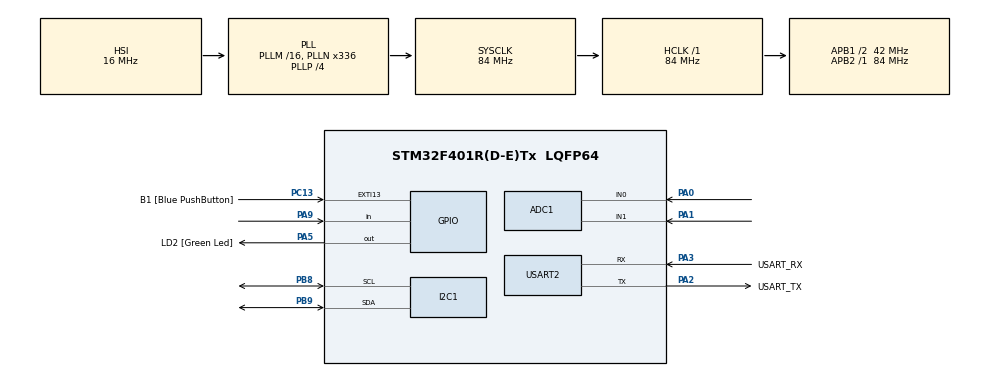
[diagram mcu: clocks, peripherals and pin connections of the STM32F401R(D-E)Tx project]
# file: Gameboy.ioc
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ADC1.Channel-0\#ChannelRegularConversion=ADC_CHANNEL_0
ADC1.Channel-1\#ChannelRegularConversion=ADC_CHANNEL_0
ADC1.ContinuousConvMode=ENABLE
ADC1.DMAContinuousRequests=ENABLE
ADC1.NbrOfConversion=2
ADC1.NbrOfConversionFlag=1
ADC1.Rank-0\#ChannelRegularConversion=1
ADC1.Rank-1\#ChannelRegularConversion=2
ADC1.SamplingTime-0\#ChannelRegularConversion=ADC_SAMPLETIME_480CYCLES
ADC1.SamplingTime-1\#ChannelRegularConversion=ADC_SAMPLETIME_480CYCLES
ADC1.master=1
Dma.ADC1.0.Direction=DMA_PERIPH_TO_MEMORY
Dma.ADC1.0.FIFOMode=DMA_FIFOMODE_DISABLE
Dma.ADC1.0.Instance=DMA2_Stream0
Dma.ADC1.0.MemDataAlignment=DMA_MDATAALIGN_HALFWORD
Dma.ADC1.0.MemInc=DMA_MINC_ENABLE
Dma.ADC1.0.Mode=DMA_CIRCULAR
Dma.ADC1.0.PeriphDataAlignment=DMA_PDATAALIGN_HALFWORD
Dma.ADC1.0.PeriphInc=DMA_PINC_DISABLE
Dma.ADC1.0.Priority=DMA_PRIORITY_LOW
Dma.Request0=ADC1
FREERTOS.Mutexes01=DataMutex,Dynamic,NULL,Available
FREERTOS.Tasks01=GameTask,24,512,StartGameTask,Default,NULL,Dynamic,NULL,NULL;InputTask,40,128,StartInputTask,Default,NULL,Dynamic,NULL,NULL
I2C1.I2C_Mode=I2C_Fast
Mcu.Family=STM32F4
Mcu.Name=STM32F401R(D-E)Tx
Mcu.Package=LQFP64
NVIC.ADC_IRQn=true\:5\:0\:false\:false\:true\:true\:true\:true\:true
NVIC.DMA2_Stream0_IRQn=true\:5\:0\:false\:false\:true\:true\:false\:true\:true
NVIC.PriorityGroup=NVIC_PRIORITYGROUP_4
PA0-WKUP.Signal=ADCx_IN0
PA1.Signal=ADCx_IN1
PA13.GPIO_Label=TMS
PA13.Mode=Trace_Asynchronous_SW
PA13.Signal=SYS_JTMS-SWDIO
PA14.GPIO_Label=TCK
PA14.Mode=Trace_Asynchronous_SW
PA14.Signal=SYS_JTCK-SWCLK
PA2.GPIO_Label=USART_TX
PA2.GPIO_Mode=GPIO_MODE_AF_PP
PA2.GPIO_PuPd=GPIO_NOPULL
PA2.GPIO_Speed=GPIO_SPEED_FREQ_LOW
PA2.Mode=Asynchronous
PA2.Signal=USART2_TX
PA3.GPIO_Label=USART_RX
PA3.GPIO_Mode=GPIO_MODE_AF_PP
PA3.GPIO_PuPd=GPIO_NOPULL
PA3.GPIO_Speed=GPIO_SPEED_FREQ_LOW
PA3.Mode=Asynchronous
PA3.Signal=USART2_RX
PA5.GPIO_Label=LD2 [Green Led]
PA5.GPIO_Mode=GPIO_MODE_OUTPUT_PP
PA5.GPIO_PuPd=GPIO_NOPULL
PA5.GPIO_Speed=GPIO_SPEED_FREQ_LOW
PA5.Signal=GPIO_Output
PA9.Signal=GPIO_Input
PB3.GPIO_Label=SWO
PB3.Mode=Trace_Asynchronous_SW
PB3.Signal=SYS_JTDO-SWO
PB8.Mode=I2C
PB8.Signal=I2C1_SCL
PB9.Mode=I2C
PB9.Signal=I2C1_SDA
PC13-ANTI_TAMP.GPIO_Label=B1 [Blue PushButton]
PC13-ANTI_TAMP.GPIO_ModeDefaultEXTI=GPIO_MODE_IT_FALLING
PC13-ANTI_TAMP.GPIO_PuPd=GPIO_NOPULL
PC13-ANTI_TAMP.Signal=GPXTI13
PC14-OSC32_IN.Mode=LSE-External-Oscillator
PC14-OSC32_IN.Signal=RCC_OSC32_IN
PC15-OSC32_OUT.Mode=LSE-External-Oscillator
PC15-OSC32_OUT.Signal=RCC_OSC32_OUT
PH0\ -\ OSC_IN.Mode=HSE-External-Clock-Source
PH0\ -\ OSC_IN.Signal=RCC_OSC_IN
PH1\ -\ OSC_OUT.Mode=HSE-External-Clock-Source
PH1\ -\ OSC_OUT.Signal=RCC_OSC_OUT
ProjectManager.HeapSize=0x200
ProjectManager.StackSize=0x400
ProjectManager.TargetToolchain=STM32CubeIDE
RCC.48MHZClocksFreq_Value=48000000
RCC.AHBFreq_Value=84000000
RCC.APB1CLKDivider=RCC_HCLK_DIV2
RCC.APB1Freq_Value=42000000
RCC.APB1TimFreq_Value=84000000
RCC.APB2Freq_Value=84000000
RCC.APB2TimFreq_Value=84000000
RCC.CortexFreq_Value=84000000
RCC.HCLKFreq_Value=84000000
RCC.HSE_VALUE=8000000
RCC.HSI_VALUE=16000000
RCC.PLLN=336
RCC.PLLP=RCC_PLLP_DIV4
RCC.PLLQ=7
RCC.SYSCLKFreq_VALUE=84000000
RCC.SYSCLKSource=RCC_SYSCLKSOURCE_PLLCLK
RCC.VCOOutputFreq_Value=336000000
SH.ADCx_IN0.0=ADC1_IN0,IN0
SH.ADCx_IN1.0=ADC1_IN1,IN1
USART2.VirtualMode=VM_ASYNC
VP_FREERTOS_VS_CMSIS_V2.Mode=CMSIS_V2
board=NUCLEO-F401RE

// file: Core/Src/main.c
/* USER CODE BEGIN Header */
/**
  ******************************************************************************
  * @file           : main.c
  * @brief          : Main program body
  ******************************************************************************
  */
/* USER CODE END Header */
#include "main.h"
#include "cmsis_os.h"
#include "adc.h"
#include "dma.h"
#include "i2c.h"
#include "usart.h"
#include "gpio.h"

/* USER CODE BEGIN Includes */
#include "ssd1306.h"
#include "ssd1306_fonts.h"
#include "joystick.h"

// Note: Ensure you have included SEGGER headers if you use them below
// #include "SEGGER_SYSVIEW.h"
#include "SEGGER_SYSVIEW.h"
/* USER CODE END Includes */

/* USER CODE BEGIN PV */
#define DWT_CTRL (*(volatile uint32_t*) 0xE0001000)

// The array that DMA will fill automatically.
// 'volatile' is critical so the compiler knows hardware changes it.
volatile uint16_t adcValues[2];
/* USER CODE END PV */

void SystemClock_Config(void);
void MX_FREERTOS_Init(void);

int main(void)
{

  /* MCU Configuration--------------------------------------------------------*/

  /* Reset of all peripherals, Initializes the Flash interface and the Systick. */
  HAL_Init();

  /* Configure the system clock */
  SystemClock_Config();

  /* Initialize all configured peripherals */
  MX_GPIO_Init();
  MX_DMA_Init();
  MX_USART2_UART_Init();
  MX_ADC1_Init();
  MX_I2C1_Init();

  /* USER CODE BEGIN 2 */
  ssd1306_Init();
  Joystick_Init();

// --- DMA START (Correct!) ---
  if (HAL_ADC_Start_DMA(&hadc1, (uint32_t*)adcValues, 2) != HAL_OK) {
	  Error_Handler();
  }

// --- SYSTEMVIEW SETUP ---

// 1. Enable Cycle Counter (Required for timestamps)
  DWT_CTRL |= (1<<0);

// 2. Setup Priority Grouping (Required by FreeRTOS)
  NVIC_SetPriorityGrouping(0);

// 3. Configure SystemView (Initialize buffers)
// --- FIX: Uncomment this ---
  SEGGER_SYSVIEW_Conf();

// 4. Start Recording
// --- FIX: Uncomment this ---
//  SEGGER_SYSVIEW_Start();

// Note: I commented out SEGGER_UART_init because usually SystemView uses RTT.
// If you are sure you are using UART mode, uncomment it.
  SEGGER_UART_init(500000);

  /* USER CODE END 2 */

  /* Init scheduler */
  osKernelInitialize();  /* Call init function for freertos objects (in cmsis_os2.c) */
  MX_FREERTOS_Init();

  /* Start scheduler */
  osKernelStart();

  /* We should never get here as control is now taken by the scheduler */

  /* Infinite loop */
  while (1)
  {

  }
}

void SystemClock_Config(void)
{
  RCC_OscInitTypeDef RCC_OscInitStruct = {0};
  RCC_ClkInitTypeDef RCC_ClkInitStruct = {0};

  /** Configure the main internal regulator output voltage
  */
  __HAL_RCC_PWR_CLK_ENABLE();
  __HAL_PWR_VOLTAGESCALING_CONFIG(PWR_REGULATOR_VOLTAGE_SCALE2);

  /** Initializes the RCC Oscillators according to the specified parameters
  * in the RCC_OscInitTypeDef structure.
  */
  RCC_OscInitStruct.OscillatorType = RCC_OSCILLATORTYPE_HSI;
  RCC_OscInitStruct.HSIState = RCC_HSI_ON;
  RCC_OscInitStruct.HSICalibrationValue = RCC_HSICALIBRATION_DEFAULT;
  RCC_OscInitStruct.PLL.PLLState = RCC_PLL_ON;
  RCC_OscInitStruct.PLL.PLLSource = RCC_PLLSOURCE_HSI;
  RCC_OscInitStruct.PLL.PLLM = 16;
  RCC_OscInitStruct.PLL.PLLN = 336;
  RCC_OscInitStruct.PLL.PLLP = RCC_PLLP_DIV4;
  RCC_OscInitStruct.PLL.PLLQ = 7;
  if (HAL_RCC_OscConfig(&RCC_OscInitStruct) != HAL_OK)
  {
    Error_Handler();
  }

  /** Initializes the CPU, AHB and APB buses clocks
  */
  RCC_ClkInitStruct.ClockType = RCC_CLOCKTYPE_HCLK|RCC_CLOCKTYPE_SYSCLK
                              |RCC_CLOCKTYPE_PCLK1|RCC_CLOCKTYPE_PCLK2;
  RCC_ClkInitStruct.SYSCLKSource = RCC_SYSCLKSOURCE_PLLCLK;
  RCC_ClkInitStruct.AHBCLKDivider = RCC_SYSCLK_DIV1;
  RCC_ClkInitStruct.APB1CLKDivider = RCC_HCLK_DIV2;
  RCC_ClkInitStruct.APB2CLKDivider = RCC_HCLK_DIV1;

  if (HAL_RCC_ClockConfig(&RCC_ClkInitStruct, FLASH_LATENCY_2) != HAL_OK)
  {
    Error_Handler();
  }
}

void Error_Handler(void)
{
  __disable_irq();
  while (1)
  {
  }
}

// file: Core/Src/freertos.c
/* USER CODE BEGIN Header */
/**
  ******************************************************************************
  * File Name          : freertos.c
  * Description        : Code for freertos applications - Final Version
  ******************************************************************************
  */
/* USER CODE END Header */

#include "FreeRTOS.h"
#include "task.h"
#include "main.h"
#include "cmsis_os.h"

#include "ssd1306.h"
#include "ssd1306_fonts.h"
#include "joystick.h"
#include "gameobjects.h"
#include <stdio.h>

typedef enum {
    STATE_PLAYING,
    STATE_PAUSED,
    STATE_GAME_OVER
} GameState_t;

// --- 1. SHARED RESOURCES ---
extern volatile uint16_t adcValues[2]; // From DMA
volatile JoystickData_t public_joy_data = {2048, 2048, 1}; // Protected by Mutex
volatile GameState_t current_state = STATE_PLAYING;

// --- 2. RTOS OBJECTS ---
// Mutex (For Data Protection)
osMutexId_t DataMutexHandle;
const osMutexAttr_t DataMutex_attributes = { .name = "DataMutex" };

// Semaphore (For Button Signaling)
osSemaphoreId_t ButtonSemHandle;
const osSemaphoreAttr_t ButtonSem_attributes = { .name = "ButtonSem" };

// Queue (For LED Events)
osMessageQueueId_t LedQueueHandle;
const osMessageQueueAttr_t LedQueue_attributes = { .name = "LedQueue" };

// Tasks
osThreadId_t InputTaskHandle;
osThreadId_t GameTaskHandle;
osThreadId_t LedTaskHandle; // NEW TASK

// Task Attributes
const osThreadAttr_t InputTask_attributes = {
  .name = "InputTask",
  .stack_size = 128 * 4,
  .priority = (osPriority_t) osPriorityAboveNormal,
};
const osThreadAttr_t GameTask_attributes = {
  .name = "GameTask",
  .stack_size = 512 * 4,
  .priority = (osPriority_t) osPriorityNormal,
};
const osThreadAttr_t LedTask_attributes = {
  .name = "LedTask",
  .stack_size = 128 * 4,
  .priority = (osPriority_t) osPriorityLow, // Low priority background worker
};

/* Function Prototypes */
void StartInputTask(void *argument);
void StartGameTask(void *argument);
void StartLedTask(void *argument); // NEW

void MX_FREERTOS_Init(void);

void MX_FREERTOS_Init(void) {
  // Create Mutex
  DataMutexHandle = osMutexNew(&DataMutex_attributes);

  // Create Semaphore (Binary, starts at 0)
  ButtonSemHandle = osSemaphoreNew(1, 0, &ButtonSem_attributes);

  // Create Queue (Depth 5, Size = sizeof(uint8_t))
  LedQueueHandle = osMessageQueueNew(5, sizeof(uint8_t), &LedQueue_attributes);

  // Create Tasks
  InputTaskHandle = osThreadNew(StartInputTask, NULL, &InputTask_attributes);
  GameTaskHandle = osThreadNew(StartGameTask, NULL, &GameTask_attributes);
  LedTaskHandle = osThreadNew(StartLedTask, NULL, &LedTask_attributes);
}

/* -------------------------------------------------------------------------
   TASK 1: INPUT (High Priority)
   Uses: Mutex (Write), Semaphore (Release)
   ------------------------------------------------------------------------- */
void StartInputTask(void *argument)
{
  Joystick_Init();
  uint8_t last_btn_state = Joystick_GetButton;

  for(;;)
  {
    uint16_t raw_x = adcValues[0];
    uint16_t raw_y = adcValues[1];
    uint8_t raw_btn = Joystick_GetButton;

    // 1. MUTEX WRITE: Protect global data
    if (osMutexAcquire(DataMutexHandle, 10) == osOK) {
        public_joy_data.x = raw_x;
        public_joy_data.y = raw_y;
        public_joy_data.button = raw_btn;
        osMutexRelease(DataMutexHandle);
    }

    // 2. SEMAPHORE SIGNAL: Detect button press edge
    if (raw_btn == 0 && last_btn_state == 1) {
        // "Give" the semaphore to signal an event happened.
        // We don't change state here anymore! We just announce the event.
        osSemaphoreRelease(ButtonSemHandle);
    }

    last_btn_state = raw_btn;
    osDelay(20);
  }
}

/* -------------------------------------------------------------------------
   TASK 2: GAME ENGINE (Normal Priority)
   Uses: Mutex (Read), Semaphore (Acquire), Queue (Send)
   ------------------------------------------------------------------------- */
void StartGameTask(void *argument)
{
  ssd1306_Init();
  ssd1306_Fill(Black);
  ssd1306_UpdateScreen();

  Basket_t player;
  FallingObject_t fruit;
  Game_Init(&player, &fruit);

  int score = 0;
  char strBuf[16];
  GameState_t last_loop_state = STATE_PLAYING;

  for(;;)
  {
    // --- 1. CHECK SEMAPHORE (Button Event) ---
    // Check if InputTask signaled a button press (Don't wait, return immediately)
    if (osSemaphoreAcquire(ButtonSemHandle, 0) == osOK) {
        // Semaphore taken! A press occurred. Toggle State.
        if (current_state == STATE_PLAYING) current_state = STATE_PAUSED;
        else if (current_state == STATE_PAUSED) current_state = STATE_PLAYING;
        else if (current_state == STATE_GAME_OVER) current_state = STATE_PLAYING;
    }

    // --- 2. GET INPUT (Mutex) ---
    JoystickData_t input = {2048, 2048, 1};
    if (osMutexAcquire(DataMutexHandle, 10) == osOK) {
        input = public_joy_data;
        osMutexRelease(DataMutexHandle);
    }

    // --- 3. GAME LOGIC ---
    ssd1306_Fill(Black);

    switch (current_state) {
        case STATE_PLAYING:
            if (last_loop_state == STATE_GAME_OVER) {
                score = 0;
                Game_Init(&player, &fruit);
            }

            Basket_Update(&player, input);
            Object_Update(&fruit);

            if (Check_Collision(&player, &fruit)) {
                uint8_t msg;
                if (fruit.type == 2) { // Bomb
                    current_state = STATE_GAME_OVER;
                    msg = 2; // Event Type 2 = Bomb
                } else {
                    score++;
                    Object_Spawn(&fruit);
                    msg = 1; // Event Type 1 = Fruit Catch
                }

                // --- QUEUE SEND: Notify LED Task ---
                osMessageQueuePut(LedQueueHandle, &msg, 0, 0);
            }

            if (fruit.active == 0) Object_Spawn(&fruit);
            Game_Draw(&player, &fruit);

            sprintf(strBuf, "%d", score);
            ssd1306_SetCursor(0, 0);
            ssd1306_WriteString(strBuf, Font_7x10, White);
            break;

        case STATE_PAUSED:
            Game_Draw(&player, &fruit);
            ssd1306_SetCursor(40, 25);
            ssd1306_WriteString("PAUSED", Font_7x10, White);
            break;

        case STATE_GAME_OVER:
            ssd1306_SetCursor(30, 20);
            ssd1306_WriteString("GAME OVER", Font_7x10, White);
            sprintf(strBuf, "Score: %d", score);
            ssd1306_SetCursor(35, 40);
            ssd1306_WriteString(strBuf, Font_7x10, White);
            break;
    }

    last_loop_state = current_state;
    ssd1306_UpdateScreen();
    osDelay(33);
  }
}

/* -------------------------------------------------------------------------
   TASK 3: LED FEEDBACK (Low Priority)
   Uses: Queue (Receive)
   ------------------------------------------------------------------------- */
void StartLedTask(void *argument)
{
  uint8_t eventMsg;

  for(;;)
  {
      // Wait FOREVER for a message in the queue
      // This task consumes 0% CPU while waiting.
      if (osMessageQueueGet(LedQueueHandle, &eventMsg, NULL, osWaitForever) == osOK)
      {
          if (eventMsg == 1) {
              // FRUIT CAUGHT: Quick Blink
              HAL_GPIO_WritePin(LD2_GPIO_Port, LD2_Pin, GPIO_PIN_SET);
              osDelay(100);
              HAL_GPIO_WritePin(LD2_GPIO_Port, LD2_Pin, GPIO_PIN_RESET);
          }
          else if (eventMsg == 2) {
              // BOMB HIT: 3 Fast Blinks
              for(int i=0; i<3; i++) {
                  HAL_GPIO_WritePin(LD2_GPIO_Port, LD2_Pin, GPIO_PIN_SET);
                  osDelay(100);
                  HAL_GPIO_WritePin(LD2_GPIO_Port, LD2_Pin, GPIO_PIN_RESET);
                  osDelay(100);
              }
          }
      }
  }
}
